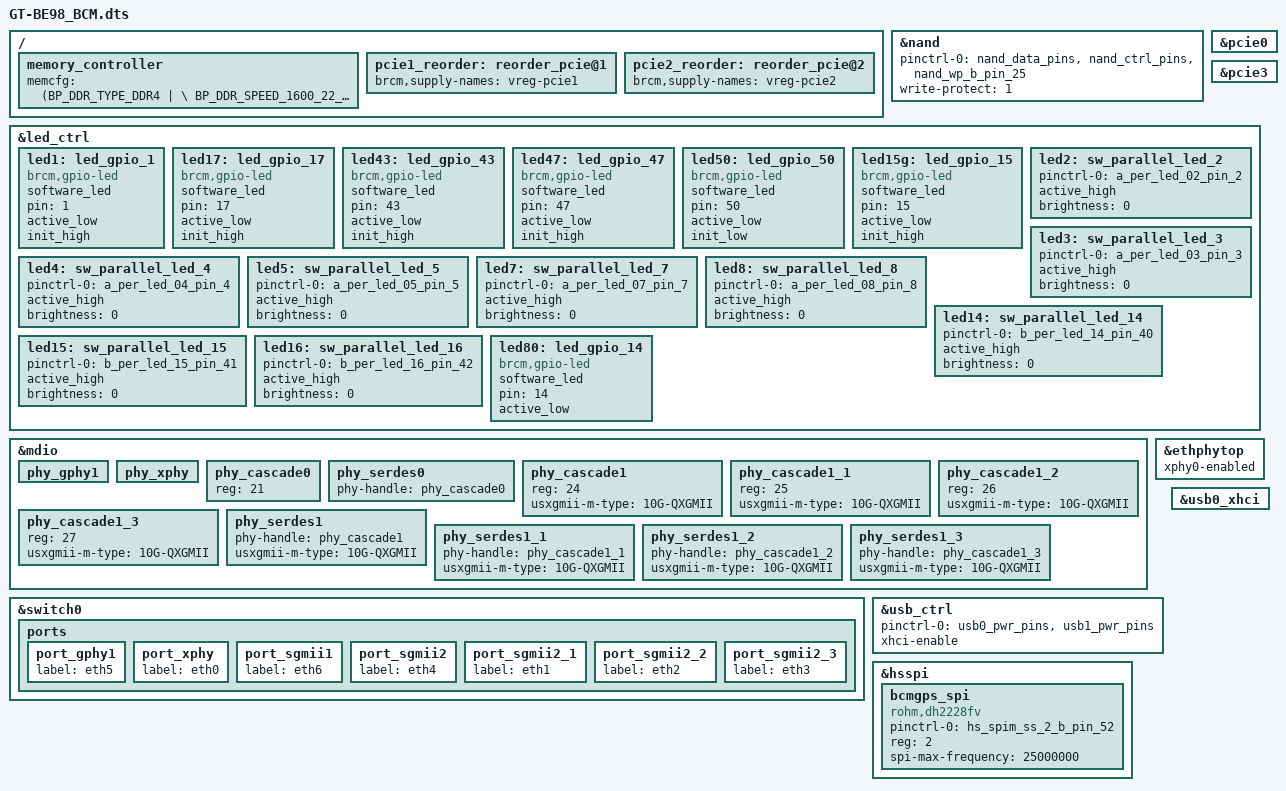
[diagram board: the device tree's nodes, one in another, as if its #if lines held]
#include "6813.dtsi"

/ {
	memory_controller {
		memcfg = <(BP_DDR_TYPE_DDR4       | \
			BP_DDR_SPEED_1600_22_22_22    | \
			BP_DDR_TOTAL_SIZE_2048MB      | \
			BP_DDR_DEVICE_WIDTH_16        | \
			BP_DDR_TOTAL_WIDTH_32BIT      | \
			BP_DDR_TEMP_EXTENDED_ASR      | \
			BP_DDR_SSC_CONFIG_1)>;
	};

//	bcmgps: bcmgps {
//		compatible = "brcm, bcmgps";
//		ext_irq = <&bca_extintr 50 GPIO_ACTIVE_HIGH (BCA_EXTINTR_TYPE_HIGH_LEVEL | BCA_EXTINTR_TYPE_SENSE_EDGE)>;   /* host_req */
//		reset-gpio = <&gpioc 48 GPIO_ACTIVE_HIGH>;  /* nStandby */
//		spi-bus = <&bcmgps_spi>;
//		status = "okay";
//	};
};

&nand {
	pinctrl-0 = <&nand_data_pins &nand_ctrl_pins &nand_wp_b_pin_25>;
	write-protect = <1>;
	status = "okay";
};

#if defined(CONFIG_BCM_PCIE_HCD) || defined(CONFIG_BCM_PCIE_HCD_MODULE)
#if defined(CONFIG_REGULATOR) && defined(CONFIG_REGULATOR_FIXED_VOLTAGE)
/**********************************************************************/
/* GPIO: Add one define per GPIO (individual or shared) regulator     */
/*       - Skip if no GPIO regulators in use                          */
/**********************************************************************/
#define PCIE0_REG_GPIO    78    /* SLEEP_0 for vreg_pcie0 node */
#define PCIE1_REG_GPIO    75    /* SLEEP_1 for vreg_pcie1 node */
#define PCIE2_REG_GPIO    76    /* SLEEP_2 for vreg_pcie2 node */
#define PCIE3_REG_GPIO    19    /* SLEEP_3 for vreg_pcie3 node */

#include "../bcm_wlan_regulator.dtsi"

/delete-node/ &pcie1;
/delete-node/ &pcie2;

/ {
	/* pcie core 1 */
	pcie1_reorder: reorder_pcie@1 {
		#define PCIE_ID			1
		#define PCIE_SPI		69
		#define PCIE_ADDR		0x80090000
		#define PCIE_SIZE		PCIE1_REG_SIZE
		#define PCIE_RANGE_ADDR		0xD0000000
		#define PCIE_RANGE_SIZE		0x10000000
		#include "../ip/bcm_pcie_core.dtsi"
	};
	/* pcie core 2 */
	pcie2_reorder: reorder_pcie@2 {
		#define PCIE_ID			2
		#define PCIE_SPI		70
		#define PCIE_ADDR		0x800A0000
		#define PCIE_SIZE		0x0000A000
		#define PCIE_RANGE_ADDR		0xE0000000
		#define PCIE_RANGE_SIZE		0x10000000
		#include "../ip/bcm_pcie_core.dtsi"
    };
};

&pcie0 {
    status = "okay";
};
 
&pcie1_reorder {
	brcm,supply-names = "vreg-pcie1";
    status = "okay";
};

&pcie2_reorder {
	brcm,supply-names = "vreg-pcie2";
    status = "okay";
};

&pcie3 {
    status = "okay";
};
#else
&pcie0 {
	status = "okay";
};
&pcie1_reorder {
	status = "okay";
};
&pcie2_reorder {
	status = "okay";
};
&pcie3 {
	status = "okay";
};
#endif
#endif //#if defined(CONFIG_BCM_PCIE_HCD) || defined(CONFIG_BCM_PCIE_HCD_MODULE)

/*
&legacy_leds {
    wl-sess-led = <&led27>;
};
*/

&led_ctrl {
	status="okay";

	/* GPIO LED */
	/* LAN LED */
	led1:led_gpio_1 {
		compatible = "brcm,gpio-led";
		software_led;
		pin = <1>;
		active_low;
		init_high;
	};
	/* WAN WHITE LED */
	led17:led_gpio_17 {
		compatible = "brcm,gpio-led";
		software_led;
		pin = <17>;
		active_low;
		init_high;
	};
	/* WAN RED LED */
	led43:led_gpio_43 {
		compatible = "brcm,gpio-led";
		software_led;
		pin = <43>;
		active_low;
		init_high;
	};
	/* 10G LAN LED */
	led47:led_gpio_47 {
		compatible = "brcm,gpio-led";
		software_led;
		pin = <47>;
		active_low;
		init_high;
	};
	/* POWER LED */
	led50:led_gpio_50 {
		compatible = "brcm,gpio-led";
		software_led;
		pin = <50>;
		active_low;
		init_low;
	};
        /* AFC LED */                                                                                                                                                                                              
        led15g:led_gpio_15 {
                compatible = "brcm,gpio-led";
                software_led;
                pin = <15>;
                active_low;
                init_high;
        };

	/* CLED */
	/* LED_1A_R */
	led2: sw_parallel_led_2 {
		pinctrl-0 = <&a_per_led_02_pin_2>;
		active_high;
		status="okay";
		brightness = <0>;
	};
	/* LED_1A_B */
	led3: sw_parallel_led_3 {
		pinctrl-0 = <&a_per_led_03_pin_3>;
		active_high;
		status="okay";
		brightness = <0>;
	};
	/* LED_1A_G */
	led4: sw_parallel_led_4 {
		pinctrl-0 = <&a_per_led_04_pin_4>;
		active_high;
		status="okay";
		brightness = <0>;
	};

	/* LED_1B_R */
	led5: sw_parallel_led_5 {
		pinctrl-0 = <&a_per_led_05_pin_5>;
		active_high;
		status="okay";
		brightness = <0>;
	};
	/* LED_1B_B */
	led7: sw_parallel_led_7 {
		pinctrl-0 = <&a_per_led_07_pin_7>;
		active_high;
		status="okay";
		brightness = <0>;
	};
	/* LED_1B_G */
	led8: sw_parallel_led_8 {
		pinctrl-0 = <&a_per_led_08_pin_8>;
		active_high;
		status="okay";
		brightness = <0>;
	};
	/* LED_1C_R */
	led14: sw_parallel_led_14 {
		pinctrl-0 = <&b_per_led_14_pin_40>;
		active_high;
		status="okay";
		brightness = <0>;
	};
	/* LED_1C_B */
	led15: sw_parallel_led_15 {
		pinctrl-0 = <&b_per_led_15_pin_41>;
		active_high;
		status="okay";
		brightness = <0>;
	};
	/* LED_1C_G */
	led16: sw_parallel_led_16 {
		pinctrl-0 = <&b_per_led_16_pin_42>;
		active_high;
		status="okay";
		brightness = <0>;
	};

	led80:led_gpio_14 {
		compatible = "brcm,gpio-led";
		software_led;
		pin = <14>;
		active_low;
	};
};

/* For AURA72UB0, NP for now
&i2c1 {
	pinctrl-names = "default";
	pinctrl-0 = <&i2c1_sclk_pin_14 &i2c1_sdata_pin_15>;
	status = "okay";
};
*/

&mdio {
    /* Port PHY mapping:
        port_gphy1 <----> phy_gphy1
        port_xphy <-----> phy_xphy      - Internal 10G PHY
        port_sgmii1 <---> phy_serdes0   - BCM84891L
        port_sgmii2 <---> phy_serdes1   - phy_cascade1
        port_sgmii2_1 <-> phy_serdes1_1 - phy_cascade1_1
        port_sgmii2_2 <-> phy_serdes1_2 - phy_cascade1_2
        port_sgmii2_3 <-> phy_serdes1_3 - phy_cascade1_3
     */
	phy_gphy1 {
		status = "okay";
	};

	phy_xphy {
		status = "okay";
	};

    phy_cascade0 {
        reg = <21>;
		status = "okay";
	};

	phy_serdes0 {
		phy-handle = <&phy_cascade0>;
		status = "okay";
	};

    phy_cascade1 {
        reg = <24>;
        usxgmii-m-type = "10G-QXGMII";  /* types: 10G-SXGMII 10G-DXGMII 10G-QXGMII 5G-SXGMII 5G-DXGMII 2.5G-SXGMII */
        status = "okay";
    };

    phy_cascade1_1 {
        reg = <25>;
        usxgmii-m-type = "10G-QXGMII";  /* types: 10G-SXGMII 10G-DXGMII 10G-QXGMII 5G-SXGMII 5G-DXGMII 2.5G-SXGMII */
        status = "okay";
    };

    phy_cascade1_2 {
        reg = <26>;
        usxgmii-m-type = "10G-QXGMII";  /* types: 10G-SXGMII 10G-DXGMII 10G-QXGMII 5G-SXGMII 5G-DXGMII 2.5G-SXGMII */
        status = "okay";
    };

    phy_cascade1_3 {
        reg = <27>;
        usxgmii-m-type = "10G-QXGMII";  /* types: 10G-SXGMII 10G-DXGMII 10G-QXGMII 5G-SXGMII 5G-DXGMII 2.5G-SXGMII */
        status = "okay";
    };

    phy_serdes1 {
        phy-handle = <&phy_cascade1>;
        usxgmii-m-type = "10G-QXGMII";  /* types: 10G-SXGMII 10G-DXGMII 10G-QXGMII 5G-SXGMII 5G-DXGMII 2.5G-SXGMII */
        status = "okay";
    };

    phy_serdes1_1 {
        phy-handle = <&phy_cascade1_1>;
        usxgmii-m-type = "10G-QXGMII";  /* types: 10G-SXGMII 10G-DXGMII 10G-QXGMII 5G-SXGMII 5G-DXGMII 2.5G-SXGMII */
        status = "okay";
    };

    phy_serdes1_2 {
        phy-handle = <&phy_cascade1_2>;
        usxgmii-m-type = "10G-QXGMII";  /* types: 10G-SXGMII 10G-DXGMII 10G-QXGMII 5G-SXGMII 5G-DXGMII 2.5G-SXGMII */
        status = "okay";
    };

    phy_serdes1_3 {
        phy-handle = <&phy_cascade1_3>;
        usxgmii-m-type = "10G-QXGMII";  /* types: 10G-SXGMII 10G-DXGMII 10G-QXGMII 5G-SXGMII 5G-DXGMII 2.5G-SXGMII */
        status = "okay";
    };
};

&ethphytop {
    xphy0-enabled;
    status = "okay";
};

&switch0 {
	ports {
		port_gphy1 {
			status = "okay";
			label = "eth5";
		};

		port_xphy {
			status = "okay";
			label = "eth0";
		};

		port_sgmii1 {
			status = "okay";
			label = "eth6";
		};

		port_sgmii2 {
			status = "okay";
			label = "eth4";
		};

		port_sgmii2_1 {
			status = "okay";
			label = "eth1";
		};

		port_sgmii2_2 {
			status = "okay";
			label = "eth2";
		};

		port_sgmii2_3 {
			status = "okay";
			label = "eth3";
		};
	};
};

&usb_ctrl {
	pinctrl-names = "default";
	pinctrl-0 = <&usb0_pwr_pins &usb1_pwr_pins>;
	status = "okay";
	xhci-enable;
};
&usb0_xhci {
	status = "okay";
};

&hsspi {
	status = "okay";
	bcmgps_spi: bcmgps_spi {
		pinctrl-names = "default"; 
		pinctrl-0 = <&hs_spim_ss_2_b_pin_52>;
		status = "okay";
		compatible = "rohm,dh2228fv";
		reg = <2>;
		spi-max-frequency = <25000000>;
	};
};
